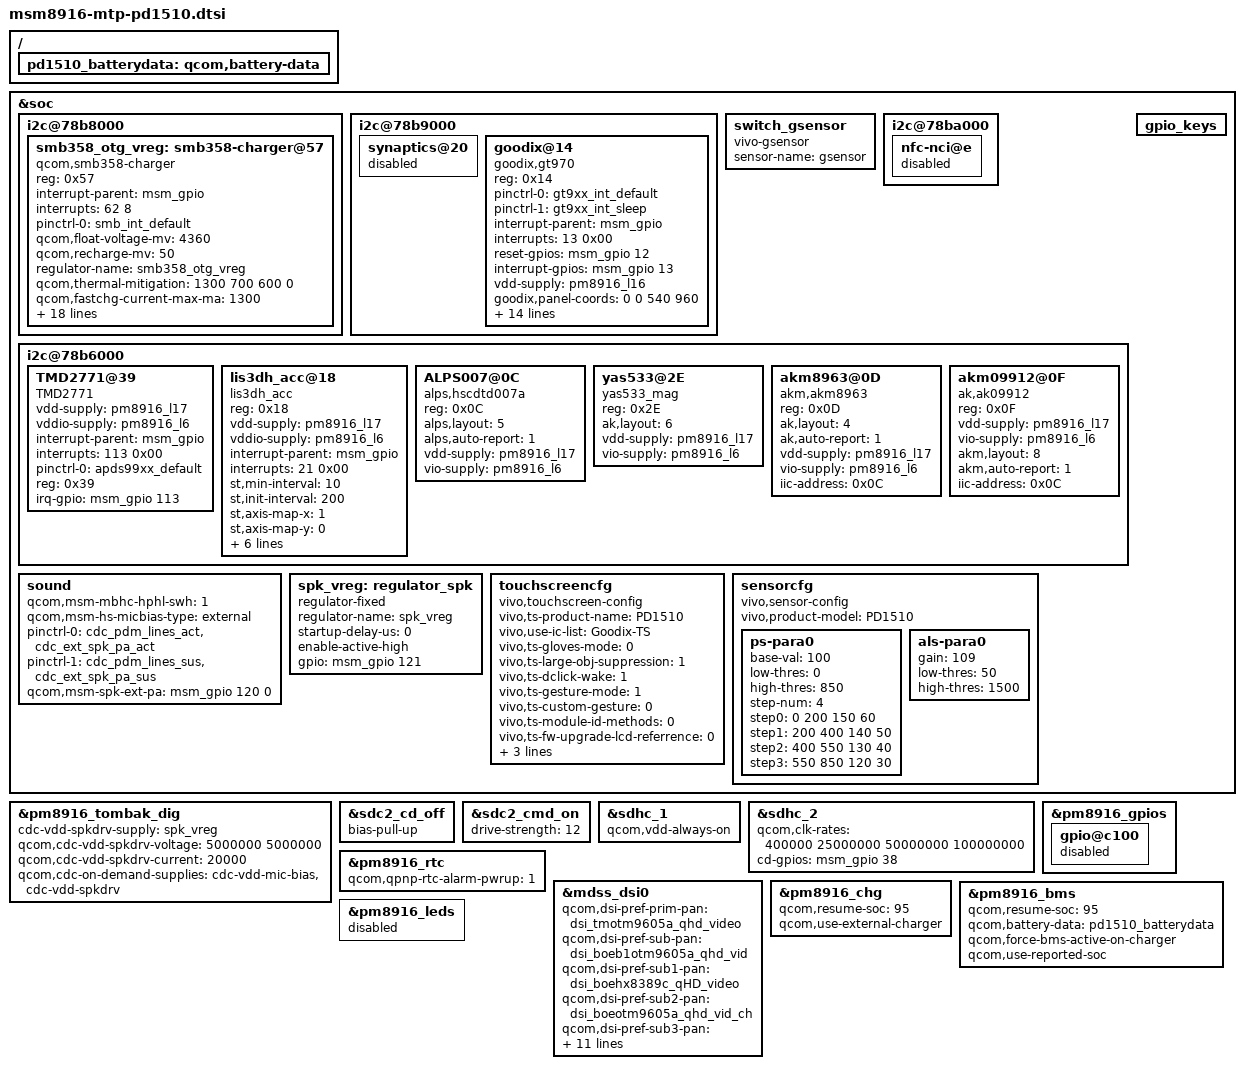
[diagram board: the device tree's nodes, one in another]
/* Copyright (c) 2018, The Linux Foundation. All rights reserved.
*  Copyright (c) 2018, Ketut P. Kumajaya.
*  Copyright (c) 2020, the_shahnawaz_sheikh (sheikhshahnawaz41299).
*
* This program is free software; you can redistribute it and/or modify
* it under the terms of the GNU General Public License version 2 and
* only version 2 as published by the Free Software Foundation.
*
* This program is distributed in the hope that it will be useful,
* but WITHOUT ANY WARRANTY; without even the implied warranty of
* MERCHANTABILITY or FITNESS FOR A PARTICULAR PURPOSE.  See the
* GNU General Public License for more details.
*/

#include "dsi-panel-tmotm9605a-qhd-video.dtsi"
#include "dsi-panel-boeb1otm9605a-qhd-video.dtsi"
#include "dsi-panel-boeotm9605a-qhd-ch-video.dtsi"
#include "dsi-panel-boeotm9605a-qhd-video.dtsi"
#include "dsi-panel-tmotm9605a-qhd-ch-video.dtsi"
#include "dsi-panel-tryhx8389c-qHD-ch-video.dtsi"
#include "dsi-panel-tryhx8389c-qHD-video.dtsi"
#include "dsi-panel-boehx8389c-qHD-video.dtsi"
#include "msm8916-camera-sensor-mtp-pd1510.dtsi"
#include "msm8916-pinctrl-pd1510.dtsi"
#include "msm8916-common-pd1510.dtsi"


&soc {

	i2c@78b8000 {
		smb358_otg_vreg: smb358-charger@57 {
			compatible = "qcom,smb358-charger";
			reg = <0x57>;
			interrupt-parent = <&msm_gpio>;
			interrupts = <62 8>;
			pinctrl-names = "default";
			pinctrl-0 = <&smb_int_default>;

			qcom,float-voltage-mv = <4360>;
			qcom,recharge-mv = <50>;
			//qcom,recharge-disabled;
			regulator-name = "smb358_otg_vreg";
			qcom,thermal-mitigation = <1300 700 600 0>;
			qcom,fastchg-current-max-ma = <1300>;

			qcom,disable-apsd;
			qcom,bms-psy-name = "bms";
			/* qcom,iterm-disabled; */
			qcom,iterm-ma = <100>;
			qcom,bms-controlled-charging;
			qcom,chg-inhibit-disabled;
			qcom,chg-vadc = <&pm8916_vadc>;
			qcom,chg-adc_tm = <&pm8916_adc_tm>;
			//qcom,vcc-i2c-supply = <&pm8916_l5>;
			qcom,irq-gpio = <&msm_gpio 62 2>;

			qcom,using-pmic-therm;
			qcom,hot-bat-decidegc = <500>;
			qcom,cold-bat-decidegc = <0>;
			qcom,bat-present-decidegc = <200>;
			/*
			 * Below properties are used for enable JEITA
			 */
			qcom,warm-bat-decidegc = <450>;
			qcom,cool-bat-decidegc = <150>;
			qcom,warm-bat-ma = <1000>;
			qcom,cool-bat-ma = <720>;
			qcom,warm-bat-mv = <4100>;
			qcom,cool-bat-mv = <4350>;
			status = "ok";
		};
	};

	

	i2c@78b9000 { /* BLSP1 QUP5 */
		synaptics@20 {
			status = "disabled";
		};
	
		goodix@14 { //gt915L
			compatible = "goodix,gt970";
			reg = <0x14>;
			/* pins used by touchscreen */
			pinctrl-names = "gt9xx_int_default","gt9xx_int_suspend";
            		pinctrl-0 = <&gt9xx_int_default>;
            		pinctrl-1 = <&gt9xx_int_sleep>;
			interrupt-parent = <&msm_gpio>;
			interrupts = <13 0x00>;
			reset-gpios = <&msm_gpio 12 0x00>;
			interrupt-gpios = <&msm_gpio 13 0x00>;
            //vcc_i2c-supply = <&pm8916_l6>;
            vdd-supply = <&pm8916_l16>;/* <&tp_power>;*/
			goodix,panel-coords = <0 0 540 960>;
			goodix,display-coords = <0 0 540 960>;
			goodix,button-map= <158 102 139>;
			goodix,family-id = <0x0>;
            goodix,i2c-pull-up;
			goodix,cfg-data0 =    //Biel
			[
				47 1C 02 07 04 0A 34 10 01 08 
				32 08 4B 32 33 35 00 00 37 13
				00 10 00 14 14 26 14 8C 2C 0D
				46 48 D3 07 D3 07 00 99 33 11
				00 00 00 00 00 00 00 08 0A A0 
				21 28 5F 94 D0 02 3C 1E 00 04
				D0 2B 00 B1 34 1E 9C 3D 00 88
				49 00 78 57 00 78 00 00 00 00 
				00 00 00 00 00 00 00 00 00 00
				00 00 00 00 F7 01 00 00 00 00
				00 00 00 00 00 14 50 00 00 00
				00 1E 1A 18 16 14 12 10 0E 0C
				0A 08 06 04 02 FF 00 00 00 00 
				00 00 00 00 08 00 00 00 DE 00
				00 41 16 18 1C 1D 1E 1F 20 21 
				22 24 26 28 14 13 12 10 0F 0C 
				0A 08 06 04 02 00 FF FF 00 00
				00 00 00 00 00 00 00 00 00 00
				00 00 00 00 1E 01
			];    
			
			goodix,cfg-data2 =    //Truly
			[
				47 1C 02 07 04 0A 34 10 01 08 
				32 08 4B 32 33 35 00 00 37 13
				00 10 00 14 14 26 14 8C 2C 0D
				46 48 D3 07 D3 07 00 99 33 11
				00 00 00 00 00 00 00 08 0A A0 
				21 28 5F 94 D0 02 3C 1E 00 04
				D0 2B 00 B1 34 1E 9C 3D 00 88
				49 00 78 57 00 78 00 00 00 00 
				00 00 00 00 00 00 00 00 00 00
				00 00 00 00 F7 01 00 00 00 00
				00 00 00 00 00 14 50 00 00 00
				00 1E 1A 18 16 14 12 10 0E 0C
				0A 08 06 04 02 FF 00 00 00 00 
				00 00 00 00 08 00 00 00 DE 00
				00 41 16 18 1C 1D 1E 1F 20 21 
				22 24 26 28 14 13 12 10 0F 0C 
				0A 08 06 04 02 00 FF FF 00 00
				00 00 00 00 00 00 00 00 00 00
				00 00 00 00 1E 01
			]; 
			
			goodix,cfg-data3 =    //Yeji
			[
				47 1C 02 07 04 0A 34 10 01 08 
				32 08 4B 32 33 35 00 00 37 13
				00 10 00 14 14 26 14 8C 2C 0D
				46 48 D3 07 D3 07 00 99 33 11
				00 00 00 00 00 00 00 08 0A A0 
				21 28 5F 94 D0 02 3C 1E 00 04
				D0 2B 00 B1 34 1E 9C 3D 00 88
				49 00 78 57 00 78 00 00 00 00 
				00 00 00 00 00 00 00 00 00 00
				00 00 00 00 F7 01 00 00 00 00
				00 00 00 00 00 14 50 00 00 00
				00 1E 1A 18 16 14 12 10 0E 0C
				0A 08 06 04 02 FF 00 00 00 00 
				00 00 00 00 08 00 00 00 DE 00
				00 41 16 18 1C 1D 1E 1F 20 21 
				22 24 26 28 14 13 12 10 0F 0C 
				0A 08 06 04 02 00 FF FF 00 00
				00 00 00 00 00 00 00 00 00 00
				00 00 00 00 1E 01
		      ];                                  
				
			ts-suspend-resume=<0>;
			ts-fixed-key-type=<1>; /*0=0d,1=2d */
			
			/*--virtualkeys: EV_KEY:KEY_MENU:cx:cy:w:h:EV_KEY:KEY_HOMEPAGE:cx:cy:w:h:EV_KEY:KEY_BACK:cx:cy:w:h--*/
			ts-virt-key="0x01:139:90:1028:120:90:0x01:251:181:1028:62:90:0x01:172:272:1028:120:90:0x01:251:368:1028:72:90:0x01:158:464:1028:120:90";
		};
	};
	


         switch_gsensor {
		  compatible = "vivo-gsensor";
		  sensor-name = "gsensor";
		/*  sensor,gpio-irq = <&msm_gpio 21 0x00>;  */
	  };

	i2c@78ba000 { /* BLSP1 QUP6 */
		status = "okay";

		nfc-nci@e {
			status = "disabled";
		};
	};

	i2c@78b6000 { /* BLSP1 QUP2 */
		/delete-node/ mpu6050@68;
		/delete-node/ avago@39;
		/delete-node/ akm@c;

		TMD2771@39 {
			compatible = "TMD2771";
			vdd-supply = <&pm8916_l17>;
			vddio-supply = <&pm8916_l6>;
			interrupt-parent = <&msm_gpio>;
			interrupts = <113 0x00>;
			pinctrl-names = "default";
			pinctrl-0 = <&apds99xx_default>;
			reg = <0x39>;
			irq-gpio = <&msm_gpio 113 0x00>;
		};

		lis3dh_acc@18 {
			compatible = "lis3dh_acc";
			reg = <0x18>;
			vdd-supply = <&pm8916_l17>;
			vddio-supply = <&pm8916_l6>;

			interrupt-parent = <&msm_gpio>;
			interrupts = <21 0x00>;
			st,min-interval = <10>;
			st,init-interval = <200>;
			st,axis-map-x = <1>;
			st,axis-map-y = <0>;
			st,axis-map-z = <2>;
			st,g-range = <2>;
			st,negate-x = <0>;
			st,negate-y = <1>;
			st,negate-z = <0>;
			sensor,gpio-irq = <&msm_gpio 21 0x00>;
		};
		ALPS007@0C {
    		compatible = "alps,hscdtd007a";
    		reg = <0x0C>;
    		alps,layout =<5>;
    		alps,auto-report=<1>;
    		vdd-supply = <&pm8916_l17>;
    		vio-supply = <&pm8916_l6>;
    		};
		yas533@2E {
			compatible = "yas533_mag";
			reg = <0x2E>;
			ak,layout =<6>;
			vdd-supply = <&pm8916_l17>;
			vio-supply = <&pm8916_l6>;

		};
		akm8963@0D {
			compatible = "akm,akm8963";
			reg = <0x0D>;
			ak,layout =<4>;
			ak,auto-report=<1>;
			vdd-supply = <&pm8916_l17>;
			vio-supply = <&pm8916_l6>;
			iic-address=<0x0C>;
		};
		akm09912@0F{
		    compatible = "ak,ak09912";
		    reg = <0x0F>;
		    vdd-supply = <&pm8916_l17>;
		    vio-supply = <&pm8916_l6>;
		    akm,layout = <8>;
		    akm,auto-report=<1>;
		    iic-address=<0x0C>;
	    };

	};

	sound {
		qcom,msm-mbhc-hphl-swh = <1>;
		qcom,msm-hs-micbias-type = "external";
		pinctrl-names = "cdc_lines_act",
				"cdc_lines_sus";
		pinctrl-0 = <&cdc_pdm_lines_act &cdc_ext_spk_pa_act>;
		pinctrl-1 = <&cdc_pdm_lines_sus &cdc_ext_spk_pa_sus>;
		/delete-property/ pinctrl-2;
		/delete-property/ pinctrl-3;
		/delete-property/ pinctrl-4;
		/delete-property/ pinctrl-5;
		/delete-property/ qcom,cdc-us-euro-gpios;
		qcom,msm-spk-ext-pa = <&msm_gpio 120 0>;
	};

	
	

	gpio_keys {
		/delete-node/ camera_focus;
		/delete-node/ camera_snapshot;
	};

	spk_vreg: regulator_spk {
		compatible = "regulator-fixed";
		regulator-name = "spk_vreg";
		startup-delay-us = <0>;
		enable-active-high;
		gpio = <&msm_gpio 121 0>;
	};
};

&pm8916_tombak_dig {
	cdc-vdd-spkdrv-supply = <&spk_vreg>;
	qcom,cdc-vdd-spkdrv-voltage = <5000000 5000000>;
	qcom,cdc-vdd-spkdrv-current = <20000>;
	qcom,cdc-on-demand-supplies = "cdc-vdd-mic-bias",
			"cdc-vdd-spkdrv";
};

&sdc2_cd_off {
	/delete-property/ bias-disable;
	bias-pull-up;
};

&sdc2_cmd_on {
	drive-strength = <12>;
};

&sdhc_1 {
	qcom,vdd-always-on;
};

&sdhc_2 {
	qcom,clk-rates = <400000 25000000 50000000 100000000>;
	cd-gpios = <&msm_gpio 38 0>;
};


&pm8916_gpios {
	gpio@c100 { /* GPIO 2 */
		status = "disabled";
	};
};

&pm8916_rtc {
	qcom,qpnp-rtc-alarm-pwrup = <1>;
};



&mdss_dsi0 {
	qcom,dsi-pref-prim-pan = <&dsi_tmotm9605a_qhd_video>;
        
        qcom,dsi-pref-sub-pan = <&dsi_boeb1otm9605a_qhd_vid>;
	qcom,dsi-pref-sub1-pan = <&dsi_boehx8389c_qHD_video>;
        qcom,dsi-pref-sub2-pan = <&dsi_boeotm9605a_qhd_vid_ch>;
        qcom,dsi-pref-sub3-pan = <&dsi_boeotm9605a_qhd_vid>;
        qcom,dsi-pref-sub4-pan = <&dsi_tmotm9605a_qhd_vid_ch>;
        qcom,dsi-pref-sub5-pan = <&dsi_tryhx8389c_qHD_video_ch>;
        qcom,dsi-pref-sub6-pan = <&dsi_tryhx8389c_qHD_video>;

	qcom,platform-enable-gpio = <&msm_gpio 97 0>;
	qcom,platform-reset-gpio = <&msm_gpio 25 0>;
	qcom,platform-bklight-en-gpio = <&msm_gpio 8 0>;
        qcom,platform-project-fex;
};

/ {
	pd1510_batterydata: qcom,battery-data {
		/delete-node/ qcom,palladium-batterydata;

		//#include "batterydata-b76-atl-4v35-2260mah.dtsi"
		//#include "batterydata-desay-samsung-2260mah.dtsi"
		//#include "batterydata-atl-ds-4v35-2300mah.dtsi"
		#include "batterydata-samsung-ds-4v35-2300mah.dtsi"
		//#include "batterydata-atl-nvt-4v35-2300mah.dtsi"
	};
};

&pm8916_chg {
	status = "ok";
	qcom,resume-soc = <95>;
	qcom,use-external-charger;
};

&pm8916_bms {
	status = "ok";
	qcom,resume-soc = <95>;
	qcom,battery-data = <&pd1510_batterydata>;
	qcom,force-bms-active-on-charger;
    qcom,use-reported-soc;
};

&pm8916_leds {
	status = "disabled";
};



&soc {
	touchscreencfg { /* vivo ts configure */
	   compatible = "vivo,touchscreen-config";
	   vivo,ts-product-name="PD1510";
	   vivo,use-ic-list="Goodix-TS";
	   
	   /*----- function set BEG ---- */
	   vivo,ts-gloves-mode=<0>;
	   vivo,ts-large-obj-suppression=<1>;
	   vivo,ts-dclick-wake=<1>;
	   vivo,ts-gesture-mode=<1>; /*1=sold in native,2=sold in abroad,3...etc=for custom extensive*/
	   vivo,ts-custom-gesture=<0>;
	   vivo,ts-module-id-methods=<0>;/*0=by IC id,1=gpio,2=by LCD ID 3=...etc=for custom extensive*/
	   vivo,ts-fw-upgrade-lcd-referrence=<0>;
	   vivo,ts-anti-esd=<1>;
	   vivo,ts-charger-conn-judge=<1>;
	   vivo,ts-module-smt-mode=<1>; /* 0=COB,1=COF */
	   /*----- function set END ---- */

	};
	
	sensorcfg {
		compatible = "vivo,sensor-config";
		vivo,product-model = "PD1510";
		ps-para0 {
			base-val = <100>;
			low-thres = <0>;
			high-thres = <850>;
			step-num = <4>;
			step0 = <  0 200 150 60>;
			step1 = <200 400 140 50>;
			step2 = <400 550 130 40>;
			step3 = <550 850 120 30>;
		};
		
		als-para0 {
			gain = <109>;
			low-thres = <50>;
			high-thres = <1500>;
		};
	};
	
};
